AUTOSAR XML (schema 4-2-2)
package /Components
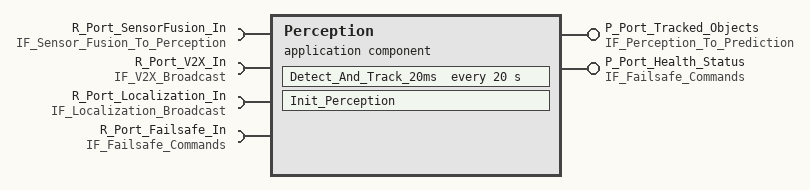
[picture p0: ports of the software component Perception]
  application sw component type Perception
    provide port P_Port_Tracked_Objects: provided-interface=IF_Perception_To_Prediction
    provide port P_Port_Health_Status: provided-interface=IF_Failsafe_Commands
    4 x require port:
      R_Port_SensorFusion_In: required-interface=IF_Sensor_Fusion_To_Perception
      R_Port_V2X_In: required-interface=IF_V2X_Broadcast
      R_Port_Localization_In: required-interface=IF_Localization_Broadcast
      R_Port_Failsafe_In: required-interface=IF_Failsafe_Commands
    behavior Perception_InternalBehavior
      init event Perception_Init: start-on-event=Init_Perception
      timing event Perception_20ms: start-on-event=Detect_And_Track_20ms, period=20
      runnable Init_Perception
        data-receive-point-by-arguments:
          access Read_Init_Localization_Status: accessed-variable={autosar-variable-in-impl-datatype={port-prototype=R_Port_Localization_In, target-data-prototype=Localization_Status_Buffer}, autosar-variable=R_Port_Localization_In.Localization_Status}
        data-send-points:
          access Send_Initial_Health_Status: accessed-variable={autosar-variable-in-impl-datatype={port-prototype=P_Port_Health_Status, target-data-prototype=Health_Status_Impl}, autosar-variable=P_Port_Health_Status.Failsafe_Status}
        data-write-access:
          access Write_Init_Tracker_Config: accessed-variable={autosar-variable-in-impl-datatype={port-prototype=P_Port_Tracked_Objects, target-data-prototype=Tracker_Config_Impl}, autosar-variable=P_Port_Tracked_Objects.Tracked_Objects}
        parameter access InitParamAccess_Localization_Status: accessed-parameter=R_Port_Localization_In.Localization_Status
      runnable Detect_And_Track_20ms: minimum-start-interval=20
        data-receive-point-by-arguments:
          9 x access:
            Read_Fused_Object_List: accessed-variable={autosar-variable-in-impl-datatype={port-prototype=R_Port_SensorFusion_In, target-data-prototype=Fused_Object_List_Buffer}, autosar-variable=R_Port_SensorFusion_In.Fused_Object_List}
            Read_Occupancy_Grid: accessed-variable={autosar-variable-in-impl-datatype={port-prototype=R_Port_SensorFusion_In, target-data-prototype=Occupancy_Grid_Buffer}, autosar-variable=R_Port_SensorFusion_In.Occupancy_Grid}
            Read_V2X_BSM: accessed-variable={autosar-variable-in-impl-datatype={port-prototype=R_Port_V2X_In, target-data-prototype=V2X_BSM_Buffer}, autosar-variable=R_Port_V2X_In.BSM}
            Read_V2X_SPAT: accessed-variable={autosar-variable-in-impl-datatype={port-prototype=R_Port_V2X_In, target-data-prototype=V2X_SPAT_Buffer}, autosar-variable=R_Port_V2X_In.SPaT}
            Read_V2X_MAP: accessed-variable={autosar-variable-in-impl-datatype={port-prototype=R_Port_V2X_In, target-data-prototype=V2X_MAP_Buffer}, autosar-variable=R_Port_V2X_In.MAP}
            Read_V2X_RSI: accessed-variable={autosar-variable-in-impl-datatype={port-prototype=R_Port_V2X_In, target-data-prototype=V2X_RSI_Buffer}, autosar-variable=R_Port_V2X_In.RSI}
            Read_Ego_Pose: accessed-variable={autosar-variable-in-impl-datatype={port-prototype=R_Port_Localization_In, target-data-prototype=Ego_Pose_Buffer}, autosar-variable=R_Port_Localization_In.Ego_Pose}
            Read_MRC_Command: accessed-variable={autosar-variable-in-impl-datatype={port-prototype=R_Port_Failsafe_In, target-data-prototype=MRC_Command_Buffer}, autosar-variable=R_Port_Failsafe_In.MRC_Command}
            Read_SOS_Command: accessed-variable={autosar-variable-in-impl-datatype={port-prototype=R_Port_Failsafe_In, target-data-prototype=SOS_Command_Buffer}, autosar-variable=R_Port_Failsafe_In.SOS_Command}
        data-send-points:
          access Send_Tracked_Objects: accessed-variable={autosar-variable-in-impl-datatype={port-prototype=P_Port_Tracked_Objects, target-data-prototype=Tracked_Objects_Impl}, autosar-variable=P_Port_Tracked_Objects.Tracked_Objects}
          access Send_Health_Status: accessed-variable={autosar-variable-in-impl-datatype={port-prototype=P_Port_Health_Status, target-data-prototype=Health_Status_Impl}, autosar-variable=P_Port_Health_Status.Failsafe_Status}
        data-write-access:
          access Write_Internal_Track_State: accessed-variable={autosar-variable-in-impl-datatype={port-prototype=P_Port_Tracked_Objects, target-data-prototype=Internal_Track_State}, autosar-variable=P_Port_Tracked_Objects.Tracked_Objects}
          access Write_Diagnostics_State: accessed-variable={autosar-variable-in-impl-datatype={port-prototype=P_Port_Health_Status, target-data-prototype=Diagnostics_State_Impl}, autosar-variable=P_Port_Health_Status.Failsafe_Status}
        parameter access RuntimeParamAccess_Localization_Status: accessed-parameter=R_Port_Localization_In.Localization_Status
